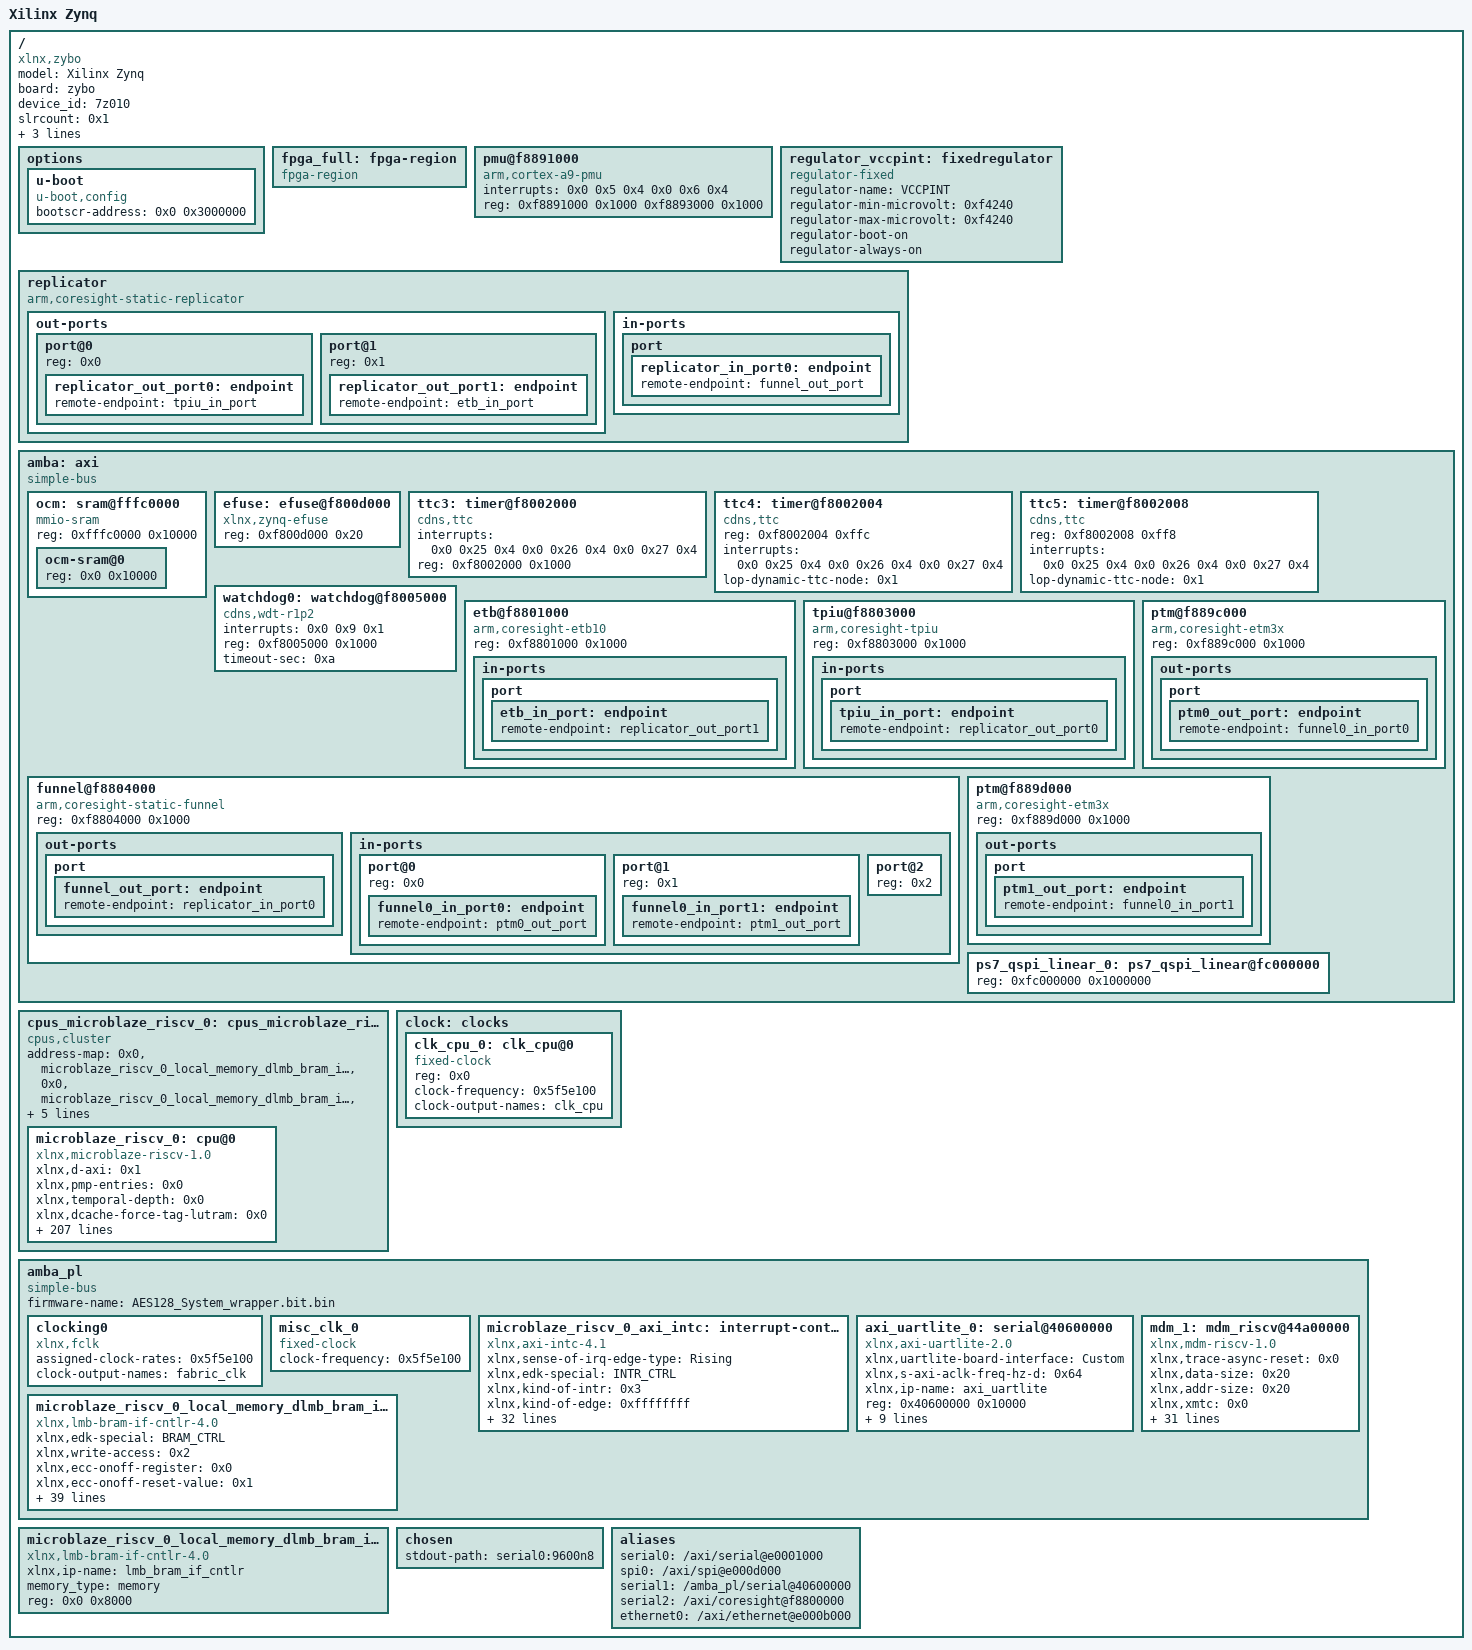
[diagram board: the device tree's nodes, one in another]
/dts-v1/;
/ {
        #address-cells = <0x1>;
        #size-cells = <0x1>;
        compatible = "xlnx,zybo";
        model = "Xilinx Zynq";
        board = "zybo";
        device_id = "7z010";
        slrcount = <0x1>;
        family = "Zynq";
        speed_grade = "1";
        pruned-sdt = <0x1>;

        options {

                u-boot {
                        compatible = "u-boot,config";
                        bootscr-address = <0x0 0x3000000>;
                };
        };

        fpga_full: fpga-region {
                phandle = <0x38>;
                compatible = "fpga-region";
                #address-cells = <0x1>;
                #size-cells = <0x1>;
                ranges;
        };

        pmu@f8891000 {
                compatible = "arm,cortex-a9-pmu";
                interrupts = <0x0 0x5 0x4 0x0 0x6 0x4>;
                reg = <0xf8891000 0x1000 0xf8893000 0x1000>;
        };

        regulator_vccpint: fixedregulator {
                phandle = <0x26>;
                compatible = "regulator-fixed";
                regulator-name = "VCCPINT";
                regulator-min-microvolt = <0xf4240>;
                regulator-max-microvolt = <0xf4240>;
                regulator-boot-on;
                regulator-always-on;
        };

        replicator {
                compatible = "arm,coresight-static-replicator";
                clock-names = "apb_pclk", "dbg_trc", "dbg_apb";

                out-ports {
                        #address-cells = <0x1>;
                        #size-cells = <0x0>;

                        port@0 {
                                reg = <0x0>;

                                replicator_out_port0: endpoint {
                                        phandle = <0x2b>;
                                        remote-endpoint = <&tpiu_in_port>;
                                };
                        };

                        port@1 {
                                reg = <0x1>;

                                replicator_out_port1: endpoint {
                                        phandle = <0x2a>;
                                        remote-endpoint = <&etb_in_port>;
                                };
                        };
                };

                in-ports {

                        port {

                                replicator_in_port0: endpoint {
                                        phandle = <0x2c>;
                                        remote-endpoint = <&funnel_out_port>;
                                };
                        };
                };
        };

        amba: axi {
                phandle = <0x1>;
                bootph-all;
                compatible = "simple-bus";
                #address-cells = <0x1>;
                #size-cells = <0x1>;
                ranges;

                ocm: sram@fffc0000 {
                        phandle = <0x3d>;
                        compatible = "mmio-sram";
                        reg = <0xfffc0000 0x10000>;
                        #address-cells = <0x1>;
                        #size-cells = <0x1>;
                        ranges = <0x0 0xfffc0000 0x10000>;

                        ocm-sram@0 {
                                reg = <0x0 0x10000>;
                        };
                };

                efuse: efuse@f800d000 {
                        phandle = <0x48>;
                        compatible = "xlnx,zynq-efuse";
                        reg = <0xf800d000 0x20>;
                };

                ttc3: timer@f8002000 {
                        phandle = <0x49>;
                        interrupts = <0x0 0x25 0x4 0x0 0x26 0x4 0x0 0x27 0x4>;
                        compatible = "cdns,ttc";
                        reg = <0xf8002000 0x1000>;
                };

                ttc4: timer@f8002004 {
                        phandle = <0x56>;
                        reg = <0xf8002004 0xffc>;
                        compatible = "cdns,ttc";
                        interrupts = <0x0 0x25 0x4 0x0 0x26 0x4 0x0 0x27 0x4>;
                        lop-dynamic-ttc-node = <0x1>;
                };

                ttc5: timer@f8002008 {
                        phandle = <0x57>;
                        reg = <0xf8002008 0xff8>;
                        compatible = "cdns,ttc";
                        interrupts = <0x0 0x25 0x4 0x0 0x26 0x4 0x0 0x27 0x4>;
                        lop-dynamic-ttc-node = <0x1>;
                };

                watchdog0: watchdog@f8005000 {
                        phandle = <0x4b>;
                        compatible = "cdns,wdt-r1p2";
                        interrupts = <0x0 0x9 0x1>;
                        reg = <0xf8005000 0x1000>;
                        timeout-sec = <0xa>;
                };

                etb@f8801000 {
                        compatible = "arm,coresight-etb10", "arm,primecell";
                        reg = <0xf8801000 0x1000>;
                        clock-names = "apb_pclk", "dbg_trc", "dbg_apb";

                        in-ports {

                                port {

                                        etb_in_port: endpoint {
                                                phandle = <0x28>;
                                                remote-endpoint = <&replicator_out_port1>;
                                        };
                                };
                        };
                };

                tpiu@f8803000 {
                        compatible = "arm,coresight-tpiu", "arm,primecell";
                        reg = <0xf8803000 0x1000>;
                        clock-names = "apb_pclk", "dbg_trc", "dbg_apb";

                        in-ports {

                                port {

                                        tpiu_in_port: endpoint {
                                                phandle = <0x27>;
                                                remote-endpoint = <&replicator_out_port0>;
                                        };
                                };
                        };
                };

                funnel@f8804000 {
                        compatible = "arm,coresight-static-funnel", "arm,primecell";
                        reg = <0xf8804000 0x1000>;
                        clock-names = "apb_pclk", "dbg_trc", "dbg_apb";

                        out-ports {

                                port {

                                        funnel_out_port: endpoint {
                                                phandle = <0x29>;
                                                remote-endpoint = <&replicator_in_port0>;
                                        };
                                };
                        };

                        in-ports {
                                #address-cells = <0x1>;
                                #size-cells = <0x0>;

                                port@0 {
                                        reg = <0x0>;

                                        funnel0_in_port0: endpoint {
                                                phandle = <0x30>;
                                                remote-endpoint = <&ptm0_out_port>;
                                        };
                                };

                                port@1 {
                                        reg = <0x1>;

                                        funnel0_in_port1: endpoint {
                                                phandle = <0x32>;
                                                remote-endpoint = <&ptm1_out_port>;
                                        };
                                };

                                port@2 {
                                        reg = <0x2>;
                                };
                        };
                };

                ptm@f889c000 {
                        compatible = "arm,coresight-etm3x", "arm,primecell";
                        reg = <0xf889c000 0x1000>;
                        clock-names = "apb_pclk", "dbg_trc", "dbg_apb";

                        out-ports {

                                port {

                                        ptm0_out_port: endpoint {
                                                phandle = <0x2d>;
                                                remote-endpoint = <&funnel0_in_port0>;
                                        };
                                };
                        };
                };

                ptm@f889d000 {
                        compatible = "arm,coresight-etm3x", "arm,primecell";
                        reg = <0xf889d000 0x1000>;
                        clock-names = "apb_pclk", "dbg_trc", "dbg_apb";

                        out-ports {

                                port {

                                        ptm1_out_port: endpoint {
                                                phandle = <0x2e>;
                                                remote-endpoint = <&funnel0_in_port1>;
                                        };
                                };
                        };
                };

                ps7_qspi_linear_0: ps7_qspi_linear@fc000000 {
                        phandle = <0x50>;
                        reg = <0xfc000000 0x1000000>;
                };
        };

        cpus_microblaze_riscv_0: cpus_microblaze_riscv@0 {
                phandle = <0x51>;
                #cpu-mask-cells = <0x1>;
                compatible = "cpus,cluster";
                #address-cells = <0x1>;
                #size-cells = <0x0>;
                address-map = <0x0 &microblaze_riscv_0_local_memory_dlmb_bram_if_cntlr_memory 0x0 0x8000>,
                 <0x0 &microblaze_riscv_0_local_memory_dlmb_bram_if_cntlr 0x0 0x8000>,
                 <0x40600000 &axi_uartlite_0 0x40600000 0x10000>,
                 <0x41200000 &microblaze_riscv_0_axi_intc 0x41200000 0x10000>,
                 <0x44a00000 &mdm_1 0x44a00000 0x10000>;
                #ranges-address-cells = <0x1>;
                #ranges-size-cells = <0x1>;

                microblaze_riscv_0: cpu@0 {
                        phandle = <0x52>;
                        xlnx,d-axi = <0x1>;
                        xlnx,pmp-entries = <0x0>;
                        xlnx,temporal-depth = <0x0>;
                        xlnx,dcache-force-tag-lutram = <0x0>;
                        reg = <0x0>;
                        xlnx,interrupt-is-edge = <0x0>;
                        xlnx,use-mmu = <0x0>;
                        xlnx,dc-axi-mon = <0x0>;
                        xlnx,debug-trace-async-reset = <0x0>;
                        xlnx,part = "xc7z010clg400-1";
                        xlnx,use-config-reset = <0x0>;
                        xlnx,family = "zynq";
                        xlnx,use-sleep = <0x0>;
                        xlnx,d-lmb = <0x1>;
                        xlnx,enable-discrete-ports = <0x0>;
                        xlnx,debug-interface = <0x0>;
                        xlnx,use-ext-brk = <0x0>;
                        xlnx,debug-enabled = <0x1>;
                        xlnx,daddr-size = <0x20>;
                        xlnx,use-extended-fsl-instr = <0x0>;
                        xlnx,branch-target-cache-size = <0x0>;
                        bus-handle = <0x35>;
                        xlnx,pmp-addr0 = <0x0>;
                        xlnx,pmp-addr1 = <0x0>;
                        xlnx,pmp-addr2 = <0x0>;
                        xlnx,pmp-addr3 = <0x0>;
                        xlnx,pmp-addr4 = <0x0>;
                        xlnx,edk-special = "microblaze_riscv";
                        xlnx,use-dcache = <0x0>;
                        xlnx,pmp-addr5 = <0x0>;
                        xlnx,use-muldiv = <0x0>;
                        xlnx,pmp-addr6 = <0x0>;
                        xlnx,use-axi-dp-ext-addr = <0x0>;
                        xlnx,pmp-addr7 = <0x0>;
                        xlnx,pmp-addr8 = <0x0>;
                        xlnx,pmp-addr9 = <0x0>;
                        xlnx,i-axi = <0x0>;
                        xlnx,icache-streams = <0x0>;
                        xlnx,i-lmb-has-prot = <0x0>;
                        xlnx,num-sync-ff-dbg-clk = <0x1>;
                        xlnx,icache-byte-size = <0x2000>;
                        xlnx,pmp-addr10 = <0x0>;
                        d-cache-size = <0x2000>;
                        xlnx,pmp-addr11 = <0x0>;
                        xlnx,pmp-addr12 = <0x0>;
                        xlnx,pmp-addr13 = <0x0>;
                        xlnx,pmp-addr14 = <0x0>;
                        xlnx,pmp-addr15 = <0x0>;
                        xlnx,avoid-primitives = <0x0>;
                        xlnx,pmp-addr16 = <0x0>;
                        xlnx,pmp-addr17 = <0x0>;
                        xlnx,pmp-addr18 = <0x0>;
                        xlnx,pdaddr-size = <0x20>;
                        xlnx,pmp-addr19 = <0x0>;
                        xlnx,pmp-addr20 = <0x0>;
                        xlnx,pmp-addr21 = <0x0>;
                        xlnx,i-lmb = <0x1>;
                        xlnx,pmp-addr22 = <0x0>;
                        xlnx,lmb-data-size = <0x20>;
                        xlnx,lockstep-select = <0x0>;
                        xlnx,pmp-addr23 = <0x0>;
                        timebase-frequency = <0x5f5e100>;
                        xlnx,pmp-addr24 = <0x0>;
                        xlnx,dcache-data-width = <0x0>;
                        xlnx,icache-force-tag-lutram = <0x0>;
                        xlnx,pmp-addr25 = <0x0>;
                        xlnx,pmp-addr26 = <0x0>;
                        xlnx,use-branch-target-cache = <0x0>;
                        xlnx,pmp-addr27 = <0x0>;
                        xlnx,number-of-pc-brk = <0x1>;
                        xlnx,pmp-addr28 = <0x0>;
                        xlnx,imprecise-exceptions = <0x0>;
                        xlnx,pmp-addr29 = <0x0>;
                        xlnx,pmp-addr30 = <0x0>;
                        xlnx,pmp-addr31 = <0x0>;
                        xlnx,pmp-addr32 = <0x0>;
                        model = "microblaze_riscv,1.0";
                        xlnx,pmp-addr33 = <0x0>;
                        xlnx,pmp-addr34 = <0x0>;
                        xlnx,pmp-addr35 = <0x0>;
                        xlnx,pmp-addr36 = <0x0>;
                        d-cache-highaddr = <0x3fffffff>;
                        xlnx,optimization = <0x0>;
                        xlnx,pmp-addr37 = <0x0>;
                        xlnx,pmp-addr38 = <0x0>;
                        xlnx,pmp-addr39 = <0x0>;
                        xlnx,pmp-addr40 = <0x0>;
                        xlnx,pmp-addr41 = <0x0>;
                        xlnx,d-lmb-mon = <0x0>;
                        xlnx,pmp-addr42 = <0x0>;
                        xlnx,pmp-addr43 = <0x0>;
                        xlnx,pmp-addr44 = <0x0>;
                        xlnx,pmp-addr45 = <0x0>;
                        xlnx,pmp-addr46 = <0x0>;
                        xlnx,pmp-addr47 = <0x0>;
                        xlnx,pmp-addr48 = <0x0>;
                        xlnx,fault-tolerant = <0x0>;
                        xlnx,pmp-addr49 = <0x0>;
                        xlnx,pmp-addr50 = <0x0>;
                        xlnx,pmp-addr51 = <0x0>;
                        xlnx,pmp-enhancements = <0x0>;
                        d-cache-line-size = <0x10>;
                        xlnx,mmu-privileged-instr = <0x0>;
                        xlnx,pmp-addr52 = <0x0>;
                        clock-frequency = <0x5f5e100>;
                        xlnx,pmp-addr53 = <0x0>;
                        xlnx,pmp-addr54 = <0x0>;
                        xlnx,pmp-addr55 = <0x0>;
                        xlnx,i-lmb-protocol = <0x0>;
                        xlnx,pmp-addr56 = <0x0>;
                        xlnx,pmp-addr57 = <0x0>;
                        xlnx,dp-axi-mon = <0x0>;
                        xlnx,pmp-addr58 = <0x0>;
                        xlnx,pmp-addr59 = <0x0>;
                        xlnx,pmp-addr60 = <0x0>;
                        xlnx,pmp-addr61 = <0x0>;
                        xlnx,pmp-addr62 = <0x0>;
                        xlnx,pmp-addr63 = <0x0>;
                        xlnx,debug-external-trace = <0x0>;
                        xlnx,addr-size = <0x20>;
                        xlnx,debug-num-progbuf = <0x2>;
                        xlnx,debug-event-counters = <0x0>;
                        xlnx,edk-iptype = "PROCESSOR";
                        xlnx,debug-latency-counters = <0x0>;
                        xlnx,interconnect = <0x2>;
                        xlnx,edge-is-positive = <0x1>;
                        xlnx,use-icache = <0x0>;
                        xlnx,async-wakeup = <0x3>;
                        xlnx,s-axi = <0x0>;
                        xlnx,use-ext-nm-brk = <0x0>;
                        xlnx,ic-axi-mon = <0x0>;
                        xlnx,archid = <0x1>;
                        xlnx,num-sync-ff-clk-irq = <0x1>;
                        xlnx,freq = <0x5f5e100>;
                        xlnx,lockstep-master = <0x0>;
                        xlnx,pmp-cfg0 = <0x0>;
                        xlnx,pmp-cfg1 = <0x0>;
                        xlnx,iaddr-size = <0x20>;
                        xlnx,interrupt-mon = <0x0>;
                        xlnx,pmp-cfg2 = <0x0>;
                        xlnx,number-of-wr-addr-brk = <0x0>;
                        xlnx,pmp-cfg3 = <0x0>;
                        xlnx,pmp-cfg4 = <0x0>;
                        xlnx,use-interrupt = <0x2>;
                        xlnx,pmp-cfg5 = <0x0>;
                        xlnx,async-interrupt = <0x1>;
                        xlnx,pc-width = <0xf>;
                        xlnx,pmp-cfg6 = <0x0>;
                        xlnx,icache-victims = <0x0>;
                        xlnx,pmp-cfg7 = <0x0>;
                        xlnx,pmp-cfg8 = <0x0>;
                        xlnx,pmp-cfg9 = <0x0>;
                        xlnx,use-bitman-a = <0x0>;
                        xlnx,use-bitman-b = <0x0>;
                        xlnx,use-bitman-c = <0x0>;
                        xlnx,i-lmb-mon = <0x0>;
                        xlnx,dcache-byte-size = <0x2000>;
                        xlnx,data-size = <0x20>;
                        compatible = "xlnx,microblaze-riscv-1.0", "xlnx,microblaze_riscv";
                        xlnx,pmp-debug-inhibit = <0x0>;
                        xlnx,use-sstc = <0x1>;
                        xlnx,fsl-exception = <0x0>;
                        xlnx,dcache-use-writeback = <0x0>;
                        device_type = "cpu";
                        xlnx,impid = <0x1>;
                        xlnx,use-bitman-s = <0x0>;
                        xlnx,base-vectors = <0x0>;
                        xlnx,icache-line-len = <0x4>;
                        xlnx,d-lmb-has-prot = <0x0>;
                        xlnx,use-barrel = <0x1>;
                        xlnx,misaligned-exceptions = <0x1>;
                        xlnx,piaddr-size = <0x20>;
                        xlnx,use-bitman = <0x0>;
                        xlnx,dcache-line-len = <0x4>;
                        xlnx,num-sync-ff-clk = <0x2>;
                        xlnx,memory-ip-list = "microblaze_riscv_0_local_memory_ilmb_bram_if_cntlr_memory", "microblaze_riscv_0_local_memory_dlmb_bram_if_cntlr_memory";
                        xlnx,number-of-rd-addr-brk = <0x0>;
                        xlnx,use-counters = <0x1>;
                        xlnx,lockstep-slave = <0x0>;
                        interrupt-handle = <0x6>;
                        xlnx,pmp-cfg10 = <0x0>;
                        xlnx,pmp-cfg11 = <0x0>;
                        xlnx,debug-profile-size = <0x0>;
                        xlnx,pmp-cfg12 = <0x0>;
                        xlnx,pmp-cfg13 = <0x0>;
                        xlnx,pmp-cfg14 = <0x0>;
                        xlnx,pmp-cfg15 = <0x0>;
                        xlnx,debug-counter-width = <0x40>;
                        xlnx,icache-data-width = <0x0>;
                        xlnx,ip-name = "microblaze_riscv";
                        xlnx,ip-axi-mon = <0x0>;
                        xlnx,d-lmb-protocol = <0x0>;
                        xlnx,trace = <0x0>;
                        xlnx,ill-instr-exception = <0x2>;
                        xlnx,debug-trace-size = <0x0>;
                        xlnx,pmp-granularity = <0x2>;
                        xlnx,num-sync-ff-dbg-trace-clk = <0x2>;
                        xlnx,ecc-use-ce-exception = <0x0>;
                        xlnx,num-sync-ff-clk-debug = <0x2>;
                        xlnx,use-atomic = <0x0>;
                        xlnx,g-template-list = <0x0>;
                        xlnx,trap-enhancement = <0x0>;
                        xlnx,hartid = <0x0>;
                        xlnx,use-fpu = <0x0>;
                        xlnx,use-non-secure = <0x0>;
                        d-cache-baseaddr = <0x0>;
                        xlnx,use-compression = <0x0>;
                        xlnx,instr-size = <0x20>;
                        xlnx,fsl-links = <0x0>;
                        xlnx,dcache-victims = <0x0>;
                        xlnx,pmp-read-only = <0x0>;
                };
        };

        clock: clocks {
                phandle = <0x53>;
                #address-cells = <0x1>;
                #size-cells = <0x0>;

                clk_cpu_0: clk_cpu@0 {
                        phandle = <0x54>;
                        compatible = "fixed-clock";
                        reg = <0x0>;
                        clock-frequency = <0x5f5e100>;
                        clock-output-names = "clk_cpu";
                        #clock-cells = <0x0>;
                };
        };

        amba_pl: amba_pl {
                phandle = <0x35>;
                ranges;
                compatible = "simple-bus";
                #address-cells = <0x1>;
                #size-cells = <0x1>;
                firmware-name = "AES128_System_wrapper.bit.bin";

                clocking0: clocking0 {
                        phandle = <0x55>;
                        compatible = "xlnx,fclk";
                        assigned-clock-rates = <0x5f5e100>;
                        #clock-cells = <0x0>;
                        clock-output-names = "fabric_clk";
                };

                misc_clk_0: misc_clk_0 {
                        phandle = <0x36>;
                        compatible = "fixed-clock";
                        clock-frequency = <0x5f5e100>;
                        #clock-cells = <0x0>;
                };

                microblaze_riscv_0_axi_intc: interrupt-controller@41200000 {
                        phandle = <0x6>;
                        #interrupt-cells = <0x2>;
                        xlnx,sense-of-irq-edge-type = "Rising";
                        xlnx,edk-special = "INTR_CTRL";
                        xlnx,kind-of-intr = <0x3>;
                        xlnx,kind-of-edge = <0xffffffff>;
                        xlnx,irq-is-level = <0x1>;
                        xlnx,has-ivr = <0x1>;
                        compatible = "xlnx,axi-intc-4.1", "xlnx,xps-intc-1.00.a";
                        xlnx,disable-synchronizers = <0x1>;
                        xlnx,kind-of-lvl = <0xffffffff>;
                        xlnx,ivar-reset-value = <0x10>;
                        xlnx,irq-active = <0x1>;
                        xlnx,en-cascade-mode = <0x0>;
                        xlnx,ip-name = "axi_intc";
                        xlnx,has-ilr = <0x0>;
                        reg = <0x41200000 0x10000>;
                        xlnx,addr-width = <0x20>;
                        clocks = <&misc_clk_0>,
                         <&misc_clk_0>;
                        xlnx,s-axi-aclk-freq-mhz = <0x64>;
                        xlnx,num-sw-intr = <0x0>;
                        xlnx,irq-connection = <0x0>;
                        xlnx,num-intr-inputs = <0x2>;
                        xlnx,has-sie = <0x1>;
                        xlnx,enable-async = <0x0>;
                        xlnx,has-cie = <0x1>;
                        xlnx,num-sync-ff = <0x2>;
                        xlnx,edk-iptype = "PERIPHERAL";
                        xlnx,mb-clk-not-connected = <0x1>;
                        xlnx,has-ipr = <0x1>;
                        xlnx,sense-of-irq-level-type = "Active_High";
                        xlnx,cascade-master = <0x0>;
                        xlnx,processor-clk-freq-mhz = <0x64>;
                        status = "okay";
                        xlnx,is-fast = <0x1>;
                        clock-names = "processor_clk", "s_axi_aclk";
                        xlnx,has-fast = <0x1>;
                        xlnx,ivar-rst-val = <0x10>;
                        interrupt-controller;
                        xlnx,async-intr = <0xffffffff>;
                        xlnx,name = "microblaze_riscv_0_axi_intc";
                };

                axi_uartlite_0: serial@40600000 {
                        phandle = <0x5>;
                        compatible = "xlnx,axi-uartlite-2.0", "xlnx,xps-uartlite-1.00.a";
                        xlnx,uartlite-board-interface = "Custom";
                        xlnx,s-axi-aclk-freq-hz-d = <0x64>;
                        xlnx,ip-name = "axi_uartlite";
                        reg = <0x40600000 0x10000>;
                        xlnx,baudrate = <0x2580>;
                        clocks = <&misc_clk_0>;
                        current-speed = <0x2580>;
                        xlnx,use-parity = <0x0>;
                        xlnx,edk-iptype = "PERIPHERAL";
                        xlnx,odd-parity = <0x0>;
                        status = "okay";
                        clock-names = "s_axi_aclk";
                        xlnx,name = "axi_uartlite_0";
                        xlnx,data-bits = <0x8>;
                        xlnx,parity = "No_Parity";
                };

                mdm_1: mdm_riscv@44a00000 {
                        phandle = <0x7>;
                        xlnx,trace-async-reset = <0x0>;
                        compatible = "xlnx,mdm-riscv-1.0";
                        xlnx,data-size = <0x20>;
                        xlnx,addr-size = <0x20>;
                        xlnx,xmtc = <0x0>;
                        xlnx,avoid-primitives = <0x0>;
                        xlnx,bscanid = <0x0>;
                        xlnx,trace-output = <0x0>;
                        xlnx,debug-interface = <0x0>;
                        xlnx,use-uart = <0x1>;
                        xlnx,mb-dbg-ports = <0x1>;
                        xlnx,jtag-chain = <0x2>;
                        xlnx,ext-trig-reset-value = <0xf1234>;
                        xlnx,trig-in-ports = <0x1>;
                        xlnx,ip-name = "mdm_riscv";
                        xlnx,brk = <0x0>;
                        xlnx,dbg-reg-access = <0x0>;
                        xlnx,use-bscan-switch = <0x0>;
                        reg = <0x44a00000 0x10000>;
                        clocks = <&misc_clk_0>;
                        xlnx,use-bscan = <0x0>;
                        xlnx,trace-id = <0x6e>;
                        xlnx,lmb-protocol = <0x0>;
                        xlnx,dtm-idcode = <0x93>;
                        xlnx,trace-data-width = <0x20>;
                        xlnx,edk-iptype = "PERIPHERAL";
                        xlnx,use-jtag-bscan = <0x1>;
                        xlnx,interconnect = <0x2>;
                        xlnx,use-cross-trigger = <0x0>;
                        xlnx,trace-protocol = <0x1>;
                        status = "okay";
                        clock-names = "S_AXI_ACLK";
                        xlnx,use-config-reset = <0x0>;
                        xlnx,trig-out-ports = <0x1>;
                        xlnx,device = "xc7z010";
                        xlnx,dbg-mem-access = <0x0>;
                        xlnx,trace-clk-out-phase = <0x5a>;
                        xlnx,name = "mdm_1";
                };

                microblaze_riscv_0_local_memory_dlmb_bram_if_cntlr: lmb_bram_if_cntlr@0 {
                        phandle = <0x34>;
                        xlnx,edk-special = "BRAM_CTRL";
                        xlnx,write-access = <0x2>;
                        compatible = "xlnx,lmb-bram-if-cntlr-4.0", "xlnx,axi-bram-ctrl";
                        xlnx,ecc-onoff-register = <0x0>;
                        xlnx,ecc-onoff-reset-value = <0x1>;
                        xlnx,s-axi-ctrl-protocol = "AXI4LITE";
                        xlnx,mask = <0x200000>;
                        xlnx,mask1 = <0x800000>;
                        xlnx,mask2 = <0x800000>;
                        xlnx,fault-inject = <0x0>;
                        xlnx,mask3 = <0x800000>;
                        xlnx,ip-name = "lmb_bram_if_cntlr";
                        xlnx,arbitration = <0x0>;
                        xlnx,num-lmb = <0x1>;
                        xlnx,mask4 = <0x800000>;
                        reg = <0x0 0x8000>;
                        xlnx,s-axi-ctrl-addr-width = <0x20>;
                        xlnx,mask5 = <0x800000>;
                        xlnx,ecc-status-registers = <0x0>;
                        xlnx,prot-cfg = <0xff>;
                        xlnx,mask6 = <0x800000>;
                        xlnx,lmb-protocol = <0x0>;
                        xlnx,ce-counter-width = <0x0>;
                        xlnx,prot-cfg1 = <0xff>;
                        xlnx,mask7 = <0x800000>;
                        xlnx,ecc = <0x0>;
                        xlnx,edk-iptype = "PERIPHERAL";
                        xlnx,prot-cfg2 = <0xff>;
                        xlnx,lmb-dwidth = <0x20>;
                        xlnx,interconnect = <0x0>;
                        xlnx,ce-failing-registers = <0x0>;
                        xlnx,prot-cfg3 = <0xff>;
                        xlnx,ue-failing-registers = <0x0>;
                        xlnx,prot-cfg4 = <0xff>;
                        xlnx,lmb-has-prot = <0x0>;
                        status = "okay";
                        xlnx,data-width = <0x20>;
                        xlnx,prot-cfg5 = <0xff>;
                        xlnx,s-axi-ctrl-data-width = <0x20>;
                        xlnx,prot-cfg6 = <0xff>;
                        xlnx,bram-awidth = <0x20>;
                        xlnx,prot-cfg7 = <0xff>;
                        xlnx,lmb-awidth = <0x20>;
                        xlnx,name = "microblaze_riscv_0_local_memory_dlmb_bram_if_cntlr";
                };
        };

        microblaze_riscv_0_local_memory_dlmb_bram_if_cntlr_memory: memory@0 {
                phandle = <0x33>;
                compatible = "xlnx,lmb-bram-if-cntlr-4.0";
                xlnx,ip-name = "lmb_bram_if_cntlr";
                device_type = "memory";
                memory_type = "memory";
                reg = <0x0 0x8000>;
        };

        chosen {
                stdout-path = "serial0:9600n8";
        };

        aliases {
                serial0 = "/axi/serial@e0001000";
                spi0 = "/axi/spi@e000d000";
                serial1 = "/amba_pl/serial@40600000";
                serial2 = "/axi/coresight@f8800000";
                ethernet0 = "/axi/ethernet@e000b000";
        };

        __symbols__ {
                fpga_full = "/fpga-region";
                regulator_vccpint = "/fixedregulator";
                replicator_out_port0 = "/replicator/out-ports/port@0/endpoint";
                replicator_out_port1 = "/replicator/out-ports/port@1/endpoint";
                replicator_in_port0 = "/replicator/in-ports/port/endpoint";
                amba = "/axi";
                ocm = "/axi/sram@fffc0000";
                efuse = "/axi/efuse@f800d000";
                watchdog0 = "/axi/watchdog@f8005000";
                etb_in_port = "/axi/etb@f8801000/in-ports/port/endpoint";
                tpiu_in_port = "/axi/tpiu@f8803000/in-ports/port/endpoint";
                funnel_out_port = "/axi/funnel@f8804000/out-ports/port/endpoint";
                funnel0_in_port0 = "/axi/funnel@f8804000/in-ports/port@0/endpoint";
                funnel0_in_port1 = "/axi/funnel@f8804000/in-ports/port@1/endpoint";
                ptm0_out_port = "/axi/ptm@f889c000/out-ports/port/endpoint";
                ptm1_out_port = "/axi/ptm@f889d000/out-ports/port/endpoint";
                ps7_qspi_linear_0 = "/axi/ps7_qspi_linear@fc000000";
                cpus_microblaze_riscv_0 = "/cpus_microblaze_riscv@0";
                microblaze_riscv_0 = "/cpus_microblaze_riscv@0/cpu@0";
                clock = "/clocks";
                clk_cpu_0 = "/clocks/clk_cpu@0";
                amba_pl = "/amba_pl";
                clocking0 = "/amba_pl/clocking0";
                misc_clk_0 = "/amba_pl/misc_clk_0";
                microblaze_riscv_0_axi_intc = "/amba_pl/interrupt-controller@41200000";
                axi_uartlite_0 = "/amba_pl/serial@40600000";
                mdm_1 = "/amba_pl/mdm_riscv@44a00000";
                microblaze_riscv_0_local_memory_dlmb_bram_if_cntlr = "/amba_pl/lmb_bram_if_cntlr@0";
                microblaze_riscv_0_local_memory_dlmb_bram_if_cntlr_memory = "/memory@0";
        };
};
